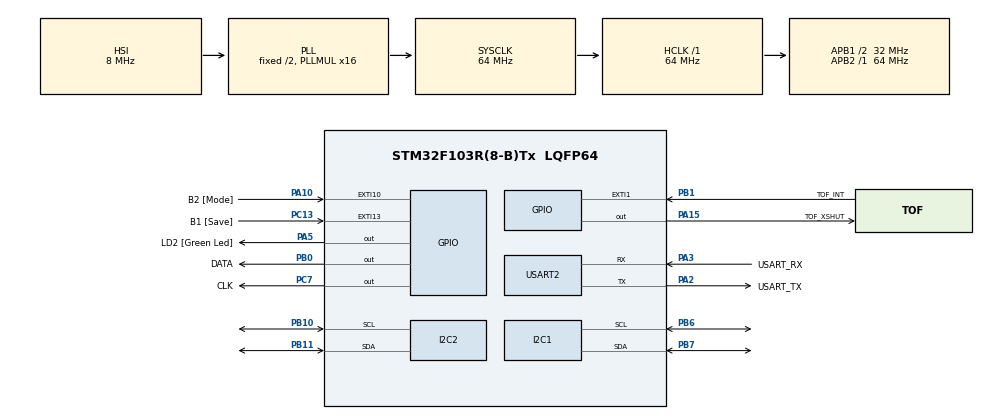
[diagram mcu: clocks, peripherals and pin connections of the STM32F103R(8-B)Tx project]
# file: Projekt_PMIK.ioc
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Mcu.Family=STM32F1
Mcu.Name=STM32F103R(8-B)Tx
Mcu.Package=LQFP64
NVIC.EXTI15_10_IRQn=true\:0\:0\:false\:false\:true\:true\:true\:true
NVIC.EXTI1_IRQn=true\:1\:0\:true\:false\:true\:true\:true\:true
NVIC.PriorityGroup=NVIC_PRIORITYGROUP_4
NVIC.TIM1_UP_IRQn=true\:0\:0\:false\:false\:true\:true\:true\:true
NVIC.TIM2_IRQn=true\:0\:0\:false\:false\:true\:true\:true\:true
NVIC.USART2_IRQn=true\:0\:0\:false\:false\:true\:true\:true\:true
PA10.GPIO_Label=B2 [Mode]
PA10.GPIO_ModeDefaultEXTI=GPIO_MODE_IT_FALLING
PA10.GPIO_PuPd=GPIO_NOPULL
PA10.Signal=GPXTI10
PA13.GPIO_Label=TMS
PA13.Mode=Serial_Wire
PA13.Signal=SYS_JTMS-SWDIO
PA14.GPIO_Label=TCK
PA14.Mode=Serial_Wire
PA14.Signal=SYS_JTCK-SWCLK
PA15.GPIO_Label=TOF_XSHUT
PA15.Signal=GPIO_Output
PA2.GPIO_Label=USART_TX
PA2.GPIO_Mode=GPIO_MODE_AF_PP
PA2.GPIO_PuPd=GPIO_NOPULL
PA2.GPIO_Speed=GPIO_SPEED_FREQ_LOW
PA2.Mode=Asynchronous
PA2.Signal=USART2_TX
PA3.GPIO_Label=USART_RX
PA3.GPIO_Mode=GPIO_MODE_AF_PP
PA3.GPIO_PuPd=GPIO_NOPULL
PA3.GPIO_Speed=GPIO_SPEED_FREQ_LOW
PA3.Mode=Asynchronous
PA3.Signal=USART2_RX
PA5.GPIO_Label=LD2 [Green Led]
PA5.GPIO_ModeDefaultOutputPP=GPIO_MODE_OUTPUT_PP
PA5.GPIO_PuPd=GPIO_NOPULL
PA5.GPIO_Speed=GPIO_SPEED_FREQ_LOW
PA5.Signal=GPIO_Output
PB0.GPIO_Label=DATA
PB0.GPIO_Speed=GPIO_SPEED_FREQ_HIGH
PB0.Signal=GPIO_Output
PB1.GPIO_Label=TOF_INT
PB1.GPIO_ModeDefaultEXTI=GPIO_MODE_IT_FALLING
PB1.GPIO_PuPd=GPIO_PULLUP
PB1.Signal=GPXTI1
PB10.Mode=I2C
PB10.Signal=I2C2_SCL
PB11.Mode=I2C
PB11.Signal=I2C2_SDA
PB3.GPIO_Label=SWO
PB3.Signal=SYS_JTDO-TRACESWO
PB6.Mode=I2C
PB6.Signal=I2C1_SCL
PB7.Mode=I2C
PB7.Signal=I2C1_SDA
PC13-TAMPER-RTC.GPIO_Label=B1 [Save]
PC13-TAMPER-RTC.GPIO_PuPd=GPIO_NOPULL
PC13-TAMPER-RTC.Signal=GPXTI13
PC14-OSC32_IN.Mode=LSE-External-Oscillator
PC14-OSC32_IN.Signal=RCC_OSC32_IN
PC15-OSC32_OUT.Mode=LSE-External-Oscillator
PC15-OSC32_OUT.Signal=RCC_OSC32_OUT
PC7.GPIO_Label=CLK
PC7.GPIO_Speed=GPIO_SPEED_FREQ_HIGH
PC7.Signal=GPIO_Output
PD0-OSC_IN.Mode=HSE-External-Clock-Source
PD0-OSC_IN.Signal=RCC_OSC_IN
PD1-OSC_OUT.Mode=HSE-External-Clock-Source
PD1-OSC_OUT.Signal=RCC_OSC_OUT
ProjectManager.HeapSize=0x200
ProjectManager.StackSize=0x400
ProjectManager.TargetToolchain=STM32CubeIDE
RCC.AHBFreq_Value=64000000
RCC.APB1CLKDivider=RCC_HCLK_DIV2
RCC.APB1Freq_Value=32000000
RCC.APB1TimFreq_Value=64000000
RCC.APB2Freq_Value=64000000
RCC.APB2TimFreq_Value=64000000
RCC.HCLKFreq_Value=64000000
RCC.PLLMUL=RCC_PLL_MUL16
RCC.RTCClockSelection=RCC_RTCCLKSOURCE_LSE
RCC.SYSCLKFreq_VALUE=64000000
RCC.SYSCLKSource=RCC_SYSCLKSOURCE_PLLCLK
RCC.USBFreq_Value=64000000
TIM1.AutoReloadPreload=TIM_AUTORELOAD_PRELOAD_ENABLE
TIM1.Period=999
TIM1.Prescaler=6399
TIM2.AutoReloadPreload=TIM_AUTORELOAD_PRELOAD_ENABLE
TIM2.Period=9999
TIM2.Prescaler=63999
USART2.VirtualMode=VM_ASYNC
VP_TIM1_VS_ClockSourceINT.Mode=Internal
VP_TIM2_VS_ClockSourceINT.Mode=Internal
board=NUCLEO-F103RB

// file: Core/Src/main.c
/* USER CODE BEGIN Header */
/**
 * \mainpage Laser Range Finder Documentation
 *
 * \section intro_sec Introduction
 *
 * The project was created on the subject of PMIK edition 2023Z.
 *
 * \subsection Description
 *
 * The rangefinder has 2 modes of operation continuous mode and single mode.
 * Changing modes occurs when the button is pressed. In continuous mode,
 * the display shows the current measurement from the sensor. In single mode,
 * it displays the last stored value from the EEPROM memory. When it is in
 * this mode and the button responsible for writing to EEPROM is pressed,
 * the value will be written and read (so it will also show on the display).
 *
 * \section modules_sec List of used modules
 *
 * VL54L0X laser distance sensor,
 * External EEPROM I2C Memory AT24C256,
 * 8 Bit display module on TM1637 controller,
 * NUCLEO-F103RB,
 * 2 NO buttons
 *
 * \section function_sec List of functionalities
 *
 * Distance measurement from sensor (I2C),
 * Distance Save measurement to external EEPROM (i2c),
 * Distance Communication with computer (UART) -Possibility to log measured values to computer,
 * Distance Display of the current measurement value on an 8-bit seven-segment display,
 * Distance Push-button selection of scanning mode (continuous/single),
 * Distance Reading from the external EEPROM to the display using the button,
 * Distance The device will be powered from the USB port.
 *
 ******************************************************************************
 * @file           : main.c
 * @brief          : Main program body
 * @details        : Program for operating the distance sensor for PMIK
 ******************************************************************************
 * @attention
 *
 * Copyright (c) 2023 STMicroelectronics.
 * All rights reserved.
 *
 * This software is licensed under terms that can be found in the LICENSE file
 * in the root directory of this software component.
 * If no LICENSE file comes with this software, it is provided AS-IS.
 *
 ******************************************************************************
 *
 * Created on 21.01.2024
 */
/* USER CODE END Header */
#include "main.h"
#include "i2c.h"
#include "tim.h"
#include "usart.h"
#include "gpio.h"

/* USER CODE BEGIN Includes */
#include "../Lib/TM1637.h"
#include "../Lib/EEPROM.h"
#include "../Lib/VL53_API_Interface.h"
#include "../Lib/Handler.h"

/* USER CODE END Includes */

void SystemClock_Config(void);

int main(void)
{

  /* MCU Configuration--------------------------------------------------------*/

  /* Reset of all peripherals, Initializes the Flash interface and the Systick. */
  HAL_Init();

  /* Configure the system clock */
  SystemClock_Config();

  /* Initialize all configured peripherals */
  MX_GPIO_Init();
  MX_USART2_UART_Init();
  MX_I2C1_Init();
  MX_I2C2_Init();
  MX_TIM1_Init();
  MX_TIM2_Init();
  /* USER CODE BEGIN 2 */
  hardwareInit();
  peripherialsInit();
  /* USER CODE END 2 */

  /* Infinite loop */
  /* USER CODE BEGIN WHILE */
  while (1)
  {
	  Compute(mode,status);

    /* USER CODE END WHILE */

  }
}

void SystemClock_Config(void)
{
  RCC_OscInitTypeDef RCC_OscInitStruct = {0};
  RCC_ClkInitTypeDef RCC_ClkInitStruct = {0};

  /** Initializes the RCC Oscillators according to the specified parameters
  * in the RCC_OscInitTypeDef structure.
  */
  RCC_OscInitStruct.OscillatorType = RCC_OSCILLATORTYPE_HSI;
  RCC_OscInitStruct.HSIState = RCC_HSI_ON;
  RCC_OscInitStruct.HSICalibrationValue = RCC_HSICALIBRATION_DEFAULT;
  RCC_OscInitStruct.PLL.PLLState = RCC_PLL_ON;
  RCC_OscInitStruct.PLL.PLLSource = RCC_PLLSOURCE_HSI_DIV2;
  RCC_OscInitStruct.PLL.PLLMUL = RCC_PLL_MUL16;
  if (HAL_RCC_OscConfig(&RCC_OscInitStruct) != HAL_OK)
  {
    Error_Handler();
  }

  /** Initializes the CPU, AHB and APB buses clocks
  */
  RCC_ClkInitStruct.ClockType = RCC_CLOCKTYPE_HCLK|RCC_CLOCKTYPE_SYSCLK
                              |RCC_CLOCKTYPE_PCLK1|RCC_CLOCKTYPE_PCLK2;
  RCC_ClkInitStruct.SYSCLKSource = RCC_SYSCLKSOURCE_PLLCLK;
  RCC_ClkInitStruct.AHBCLKDivider = RCC_SYSCLK_DIV1;
  RCC_ClkInitStruct.APB1CLKDivider = RCC_HCLK_DIV2;
  RCC_ClkInitStruct.APB2CLKDivider = RCC_HCLK_DIV1;

  if (HAL_RCC_ClockConfig(&RCC_ClkInitStruct, FLASH_LATENCY_2) != HAL_OK)
  {
    Error_Handler();
  }
}

void Error_Handler(void)
{
  __disable_irq();
  while (1)
  {
  }
}
